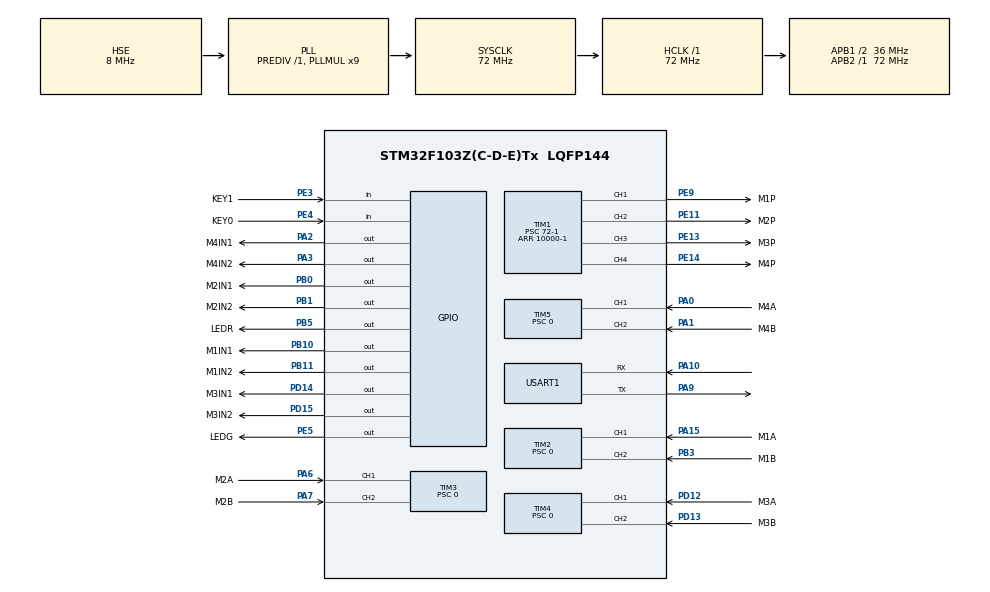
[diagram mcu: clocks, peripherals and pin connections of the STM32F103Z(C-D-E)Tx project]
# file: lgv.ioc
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Dma.Request0=USART1_RX
Dma.Request1=USART1_TX
Dma.USART1_RX.0.Direction=DMA_PERIPH_TO_MEMORY
Dma.USART1_RX.0.Instance=DMA1_Channel5
Dma.USART1_RX.0.MemDataAlignment=DMA_MDATAALIGN_BYTE
Dma.USART1_RX.0.MemInc=DMA_MINC_ENABLE
Dma.USART1_RX.0.Mode=DMA_NORMAL
Dma.USART1_RX.0.PeriphDataAlignment=DMA_PDATAALIGN_BYTE
Dma.USART1_RX.0.PeriphInc=DMA_PINC_DISABLE
Dma.USART1_RX.0.Priority=DMA_PRIORITY_VERY_HIGH
Dma.USART1_TX.1.Direction=DMA_MEMORY_TO_PERIPH
Dma.USART1_TX.1.Instance=DMA1_Channel4
Dma.USART1_TX.1.MemDataAlignment=DMA_MDATAALIGN_BYTE
Dma.USART1_TX.1.MemInc=DMA_MINC_ENABLE
Dma.USART1_TX.1.Mode=DMA_NORMAL
Dma.USART1_TX.1.PeriphDataAlignment=DMA_PDATAALIGN_BYTE
Dma.USART1_TX.1.PeriphInc=DMA_PINC_DISABLE
Dma.USART1_TX.1.Priority=DMA_PRIORITY_HIGH
Mcu.Family=STM32F1
Mcu.Name=STM32F103Z(C-D-E)Tx
Mcu.Package=LQFP144
NVIC.DMA1_Channel4_IRQn=true\:0\:0\:false\:false\:true\:false\:true\:false
NVIC.DMA1_Channel5_IRQn=true\:0\:0\:false\:false\:true\:false\:true\:false
NVIC.PriorityGroup=NVIC_PRIORITYGROUP_4
NVIC.USART1_IRQn=true\:0\:0\:false\:false\:false\:true\:false\:true
OSC_IN.Mode=HSE-External-Oscillator
OSC_IN.Signal=RCC_OSC_IN
OSC_OUT.Mode=HSE-External-Oscillator
OSC_OUT.Signal=RCC_OSC_OUT
PA0-WKUP.GPIO_Label=M4A
PA0-WKUP.Signal=S_TIM5_CH1
PA1.GPIO_Label=M4B
PA1.Signal=S_TIM5_CH2
PA10.Mode=Asynchronous
PA10.Signal=USART1_RX
PA13.Mode=Serial_Wire
PA13.Signal=SYS_JTMS-SWDIO
PA14.Mode=Serial_Wire
PA14.Signal=SYS_JTCK-SWCLK
PA15.GPIO_Label=M1A
PA15.Signal=S_TIM2_CH1_ETR
PA2.GPIO_Label=M4IN1
PA2.Signal=GPIO_Output
PA3.GPIO_Label=M4IN2
PA3.Signal=GPIO_Output
PA6.GPIO_Label=M2A
PA6.Signal=S_TIM3_CH1
PA7.GPIO_Label=M2B
PA7.Signal=S_TIM3_CH2
PA9.Mode=Asynchronous
PA9.Signal=USART1_TX
PB0.GPIO_Label=M2IN1
PB0.GPIO_ModeDefaultOutputPP=GPIO_MODE_OUTPUT_PP
PB0.GPIO_PuPd=GPIO_NOPULL
PB0.Signal=GPIO_Output
PB1.GPIO_Label=M2IN2
PB1.GPIO_PuPd=GPIO_NOPULL
PB1.Signal=GPIO_Output
PB10.GPIO_Label=M1IN1
PB10.GPIO_PuPd=GPIO_NOPULL
PB10.Signal=GPIO_Output
PB11.GPIO_Label=M1IN2
PB11.GPIO_ModeDefaultOutputPP=GPIO_MODE_OUTPUT_PP
PB11.GPIO_PuPd=GPIO_NOPULL
PB11.Signal=GPIO_Output
PB3.GPIO_Label=M1B
PB3.Signal=S_TIM2_CH2
PB5.GPIO_Label=LEDR
PB5.Signal=GPIO_Output
PC14-OSC32_IN.Mode=LSE-External-Oscillator
PC14-OSC32_IN.Signal=RCC_OSC32_IN
PC15-OSC32_OUT.Mode=LSE-External-Oscillator
PC15-OSC32_OUT.Signal=RCC_OSC32_OUT
PD12.GPIO_Label=M3A
PD12.Signal=S_TIM4_CH1
PD13.GPIO_Label=M3B
PD13.Signal=S_TIM4_CH2
PD14.GPIO_Label=M3IN1
PD14.GPIO_ModeDefaultOutputPP=GPIO_MODE_OUTPUT_PP
PD14.GPIO_PuPd=GPIO_NOPULL
PD14.Signal=GPIO_Output
PD15.GPIO_Label=M3IN2
PD15.GPIO_ModeDefaultOutputPP=GPIO_MODE_OUTPUT_PP
PD15.GPIO_PuPd=GPIO_NOPULL
PD15.Signal=GPIO_Output
PE11.GPIO_Label=M2P
PE11.Signal=S_TIM1_CH2
PE13.GPIO_Label=M3P
PE13.Signal=S_TIM1_CH3
PE14.GPIO_Label=M4P
PE14.Signal=S_TIM1_CH4
PE3.GPIO_Label=KEY1
PE3.GPIO_PuPd=GPIO_PULLUP
PE3.Signal=GPIO_Input
PE4.GPIO_Label=KEY0
PE4.GPIO_PuPd=GPIO_PULLUP
PE4.Signal=GPIO_Input
PE5.GPIO_Label=LEDG
PE5.Signal=GPIO_Output
PE9.GPIO_Label=M1P
PE9.Signal=S_TIM1_CH1
ProjectManager.HeapSize=0x200
ProjectManager.StackSize=0x400
ProjectManager.TargetToolchain=Makefile
RCC.AHBFreq_Value=72000000
RCC.APB1CLKDivider=RCC_HCLK_DIV2
RCC.APB1Freq_Value=36000000
RCC.APB1TimFreq_Value=72000000
RCC.APB2Freq_Value=72000000
RCC.APB2TimFreq_Value=72000000
RCC.HCLKFreq_Value=72000000
RCC.PLLMUL=RCC_PLL_MUL9
RCC.PLLSourceVirtual=RCC_PLLSOURCE_HSE
RCC.SYSCLKFreq_VALUE=72000000
RCC.SYSCLKSource=RCC_SYSCLKSOURCE_PLLCLK
RCC.USBFreq_Value=72000000
SH.S_TIM1_CH1.0=TIM1_CH1,PWM Generation1 CH1
SH.S_TIM1_CH2.0=TIM1_CH2,PWM Generation2 CH2
SH.S_TIM1_CH3.0=TIM1_CH3,PWM Generation3 CH3
SH.S_TIM1_CH4.0=TIM1_CH4,PWM Generation4 CH4
SH.S_TIM2_CH1_ETR.0=TIM2_CH1,Encoder_Interface
SH.S_TIM2_CH2.0=TIM2_CH2,Encoder_Interface
SH.S_TIM3_CH1.0=TIM3_CH1,Encoder_Interface
SH.S_TIM3_CH2.0=TIM3_CH2,Encoder_Interface
SH.S_TIM4_CH1.0=TIM4_CH1,Encoder_Interface
SH.S_TIM4_CH2.0=TIM4_CH2,Encoder_Interface
SH.S_TIM5_CH1.0=TIM5_CH1,Encoder_Interface
SH.S_TIM5_CH2.0=TIM5_CH2,Encoder_Interface
TIM1.AutoReloadPreload=TIM_AUTORELOAD_PRELOAD_ENABLE
TIM1.Channel-PWM\ Generation1\ CH1=TIM_CHANNEL_1
TIM1.Channel-PWM\ Generation2\ CH2=TIM_CHANNEL_2
TIM1.Channel-PWM\ Generation3\ CH3=TIM_CHANNEL_3
TIM1.Channel-PWM\ Generation4\ CH4=TIM_CHANNEL_4
TIM1.Period=10000-1
TIM1.Prescaler=72-1
TIM2.EncoderMode=TIM_ENCODERMODE_TI12
TIM2.Period=65535
TIM2.Prescaler=0
TIM3.EncoderMode=TIM_ENCODERMODE_TI12
TIM3.Period=65535
TIM3.Prescaler=0
TIM4.EncoderMode=TIM_ENCODERMODE_TI12
TIM4.Period=65535
TIM4.Prescaler=0
TIM5.EncoderMode=TIM_ENCODERMODE_TI12
TIM5.Period=65535
TIM5.Prescaler=0
USART1.VirtualMode=VM_ASYNC
board=custom

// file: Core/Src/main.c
/* USER CODE BEGIN Header */
/**
  ******************************************************************************
  * @file           : main.c
  * @brief          : Main program body
  ******************************************************************************
  * @attention
  *
  * Copyright (c) 2023 STMicroelectronics.
  * All rights reserved.
  *
  * This software is licensed under terms that can be found in the LICENSE file
  * in the root directory of this software component.
  * If no LICENSE file comes with this software, it is provided AS-IS.
  *
  ******************************************************************************
  */
/* USER CODE END Header */
#include "main.h"
#include "dma.h"
#include "tim.h"
#include "usart.h"
#include "gpio.h"

/* USER CODE BEGIN Includes */
#include "timeslice.h"
/* USER CODE END Includes */

void SystemClock_Config(void);

int main(void)
{

  /* MCU Configuration--------------------------------------------------------*/

  /* Reset of all peripherals, Initializes the Flash interface and the Systick. */
  HAL_Init();

  /* Configure the system clock */
  SystemClock_Config();

  /* Initialize all configured peripherals */
  MX_GPIO_Init();
  MX_DMA_Init();
  MX_TIM1_Init();
  MX_TIM2_Init();
  MX_TIM3_Init();
  MX_TIM4_Init();
  MX_TIM5_Init();
  MX_USART1_UART_Init();

  /* Infinite loop */
  /* USER CODE BEGIN WHILE */
  timeslice();
  while (1)
  {
    /* USER CODE END WHILE */

  }
}

void SystemClock_Config(void)
{
  RCC_OscInitTypeDef RCC_OscInitStruct = {0};
  RCC_ClkInitTypeDef RCC_ClkInitStruct = {0};

  /** Initializes the RCC Oscillators according to the specified parameters
  * in the RCC_OscInitTypeDef structure.
  */
  RCC_OscInitStruct.OscillatorType = RCC_OSCILLATORTYPE_HSE;
  RCC_OscInitStruct.HSEState = RCC_HSE_ON;
  RCC_OscInitStruct.HSEPredivValue = RCC_HSE_PREDIV_DIV1;
  RCC_OscInitStruct.HSIState = RCC_HSI_ON;
  RCC_OscInitStruct.PLL.PLLState = RCC_PLL_ON;
  RCC_OscInitStruct.PLL.PLLSource = RCC_PLLSOURCE_HSE;
  RCC_OscInitStruct.PLL.PLLMUL = RCC_PLL_MUL9;
  if (HAL_RCC_OscConfig(&RCC_OscInitStruct) != HAL_OK)
  {
    Error_Handler();
  }

  /** Initializes the CPU, AHB and APB buses clocks
  */
  RCC_ClkInitStruct.ClockType = RCC_CLOCKTYPE_HCLK|RCC_CLOCKTYPE_SYSCLK
                              |RCC_CLOCKTYPE_PCLK1|RCC_CLOCKTYPE_PCLK2;
  RCC_ClkInitStruct.SYSCLKSource = RCC_SYSCLKSOURCE_PLLCLK;
  RCC_ClkInitStruct.AHBCLKDivider = RCC_SYSCLK_DIV1;
  RCC_ClkInitStruct.APB1CLKDivider = RCC_HCLK_DIV2;
  RCC_ClkInitStruct.APB2CLKDivider = RCC_HCLK_DIV1;

  if (HAL_RCC_ClockConfig(&RCC_ClkInitStruct, FLASH_LATENCY_2) != HAL_OK)
  {
    Error_Handler();
  }
}

/* USER CODE BEGIN 4 */
#include "bsp_systick.h"
#include "bsp_gpio.h"
/* USER CODE END 4 */

void Error_Handler(void)
{
  /* USER CODE BEGIN Error_Handler_Debug */
  /* User can add his own implementation to report the HAL error return state */
  __disable_irq();
  delay_ctor();
  for (;;)
  {
    gpio_pin_toggle(LEDR_GPIO_Port, LEDR_Pin);
    delay_ms(500);
  }
  /* USER CODE END Error_Handler_Debug */
}
